# nrf51 register map
Vendor: Nordic Semiconductor; Series: nrf51; File version: 522
CPU: CM0 r3p1, little endian, no MPU, no FPU, 2 interrupt priority bits
Registers are 32-bit, read-write, reset 0x0 unless marked. A register's access mark holds for its fields unless they carry their own. Offsets are from the block's base; [hi:lo] are bit positions; {n}, {i} and the like mark numbered series; 'fields as' and 'values as' point back to an identical list.

## SPIS1 — SPI slave 1.
Base 0x40004000; alternate view of SPI1
0x24 TASKS_ACQUIRE wo — Acquire SPI semaphore.
0x28 TASKS_RELEASE wo — Release SPI semaphore.
0x104 EVENTS_END — Granted transaction completed.
0x110 EVENTS_ENDRX — End of RXD buffer reached
0x128 EVENTS_ACQUIRED — Semaphore acquired.
0x200 SHORTS — Shortcuts for SPIS.
  [2] END_ACQUIRE — Shortcut between END event and the ACQUIRE task.
    0=Disabled (Shortcut disabled.); 1=Enabled (Shortcut enabled.)
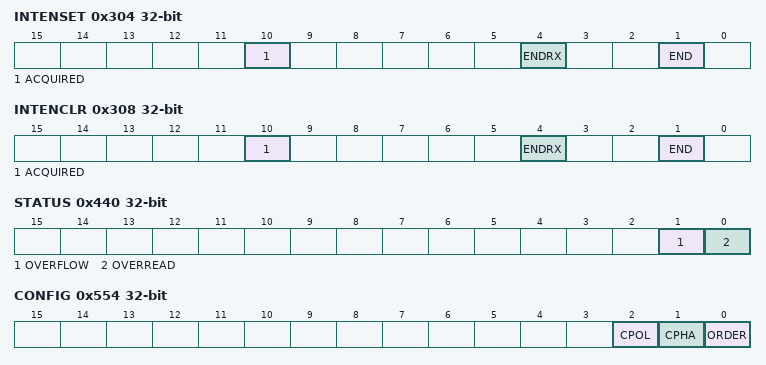
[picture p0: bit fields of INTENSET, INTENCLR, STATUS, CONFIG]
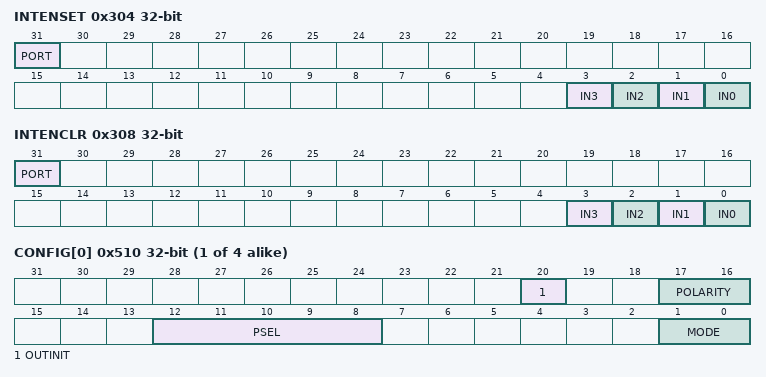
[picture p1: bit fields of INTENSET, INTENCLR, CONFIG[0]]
0x304 INTENSET — Interrupt enable set register.
  [all] fields
    on read: 0=Disabled (Interrupt disabled.); 1=Enabled (Interrupt enabled.) | on write: 1=Set (Enable interrupt on write.)
  [10] ACQUIRED — Enable interrupt on ACQUIRED event.
  [4] ENDRX — enable interrupt on ENDRX event.
  [1] END — Enable interrupt on END event.
0x308 INTENCLR — Interrupt enable clear register.
  [all] fields
    on read: 0=Disabled (Interrupt disabled.); 1=Enabled (Interrupt enabled.) | on write: 1=Clear (Disable interrupt on write.)
  [10] ACQUIRED — Disable interrupt on ACQUIRED event.
  [4] ENDRX — Disable interrupt on ENDRX event.
  [1] END — Disable interrupt on END event.
0x400 SEMSTAT ro reset 0x1 — Semaphore status.
  [1:0] SEMSTAT
    0=Free (Semaphore is free.); 1=CPU (Semaphore is assigned to the CPU.); 2=SPIS (Semaphore is assigned to the SPIS.); 3=CPUPending (Semaphore is assigned to the SPIS, but a handover to the CPU is pending.)
0x440 STATUS — Status from last transaction.
  [1] OVERFLOW — RX buffer overflow detected, and prevented.
    on read: 0=NotPresent (Error not present.); 1=Present (Error present.) | on write: 1=Clear on write
  [0] OVERREAD — TX buffer overread detected, and prevented.
    values as OVERFLOW
0x500 ENABLE — Enable SPIS.
  [2:0] ENABLE — Enable or disable SPIS.
    0=Disabled SPIS; 2=Enabled (Enable SPIS.)
0x508 PSELSCK reset 0xFFFFFFFF — Pin select for SCK.
0x50C PSELMISO reset 0xFFFFFFFF — Pin select for MISO.
0x510 PSELMOSI reset 0xFFFFFFFF — Pin select for MOSI.
0x514 PSELCSN reset 0xFFFFFFFF — Pin select for CSN.
0x534 RXDPTR — RX data pointer.
0x538 MAXRX — Maximum number of bytes in the receive buffer.
  [7:0] MAXRX
0x53C AMOUNTRX ro — Number of bytes received in last granted transaction.
  [7:0] AMOUNTRX
0x544 TXDPTR — TX data pointer.
0x548 MAXTX — Maximum number of bytes in the transmit buffer.
  [7:0] MAXTX
0x54C AMOUNTTX ro — Number of bytes transmitted in last granted transaction.
  [7:0] AMOUNTTX
0x554 CONFIG — Configuration register.
  [2] CPOL — Serial clock (SCK) polarity.
    0=ActiveHigh; 1=ActiveLow
  [1] CPHA — Serial clock (SCK) phase.
    0=Leading (Sample on leading edge of the clock. Shift serial data on trailing edge.); 1=Trailing (Sample on trailing edge of the clock. Shift serial data on leading edge.)
  [0] ORDER — Bit order.
    0=MsbFirst (Most significant bit transmitted out first.); 1=LsbFirst (Least significant bit transmitted out first.)
0x55C DEF — Default character.
  [7:0] DEF
0x5C0 ORC — Over-read character.
  [7:0] ORC
0xFFC POWER — Peripheral power control.
  [0] POWER
    0=Disabled (Module power disabled.); 1=Enabled (Module power enabled.)

## GPIOTE — GPIO tasks and events.
Base 0x40006000
{0x0+4i} TASKS_OUT[{i}] (i=0..3) wo — Tasks asssociated with GPIOTE channels.
{0x100+4i} EVENTS_IN[{i}] (i=0..3) — Tasks asssociated with GPIOTE channels.
0x17C EVENTS_PORT — Event generated from multiple pins.
0x304 INTENSET — Interrupt enable set register.
  [all] fields
    on read: 0=Disabled (Interrupt disabled.); 1=Enabled (Interrupt enabled.) | on write: 1=Set (Enable interrupt on write.)
  [31] PORT — Enable interrupt on PORT event.
  [n] IN{n} (n=0..3) — Enable interrupt on IN[{n}] event.
0x308 INTENCLR — Interrupt enable clear register.
  [all] fields
    on read: 0=Disabled (Interrupt disabled.); 1=Enabled (Interrupt enabled.) | on write: 1=Clear (Disable interrupt on write.)
  [31] PORT — Disable interrupt on PORT event.
  [n] IN{n} (n=0..3) — Disable interrupt on IN[{n}] event.
{0x510+4i} CONFIG[{i}] (i=0..3) — Channel configuration registers.
  [20] OUTINIT — Initial value of the output when the GPIOTE channel is configured as a Task.
    0=Low (Initial low output when in task mode.); 1=High (Initial high output when in task mode.)
  [17:16] POLARITY — Effects on output when in Task mode, or events on input that generates an event.
    0=None (No task or event.); 1=LoToHi (Low to high.); 2=HiToLo (High to low.); 3=Toggle
  [12:8] PSEL — Pin select.
  [1:0] MODE
    0=Disabled; 1=Event (Channel configure in event mode.); 3=Task (Channel configure in task mode.)
0xFFC POWER — Peripheral power control.
  [0] POWER
    0=Disabled (Module power disabled.); 1=Enabled (Module power enabled.)
